# G32R501 register map
Vendor: Geehy Semiconductor Co., Ltd.; Series: G32R5; File version: 1.0
CPU: CM55 r0p1, little endian, MPU, FPU, double-precision FPU, DSP, VTOR, 4 interrupt priority bits
Registers are 32-bit, read-write, reset 0x0 unless marked. A register's access mark holds for its fields unless they carry their own. Offsets are from the block's base; [hi:lo] are bit positions; {n}, {i} and the like mark numbered series.

## DCS_COMMON — Dual Code Security for common
Base 0x500240E0
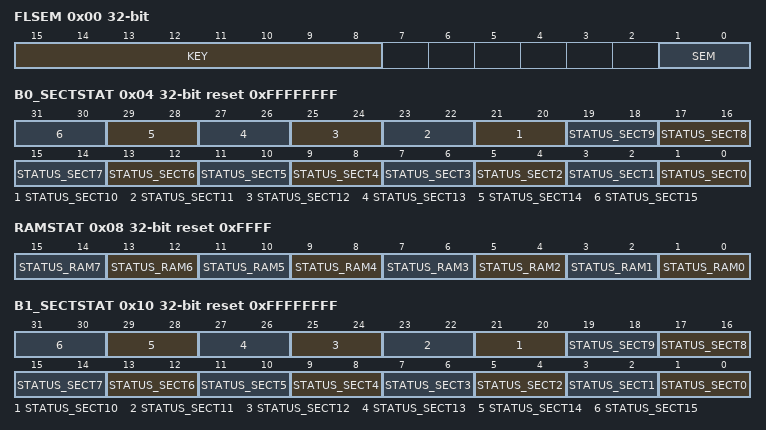
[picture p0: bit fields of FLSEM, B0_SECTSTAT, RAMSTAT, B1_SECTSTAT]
0x00 FLSEM
  [15:8] KEY
  [1:0] SEM — Flash Wrapper written mode configuration
0x04 B0_SECTSTAT ro reset 0xFFFFFFFF
  [2n+1:2n] STATUS_SECT{n} (n=0..15) — Flash BANK0 Sector x Flag
0x08 RAMSTAT ro reset 0xFFFF
  [2n+1:2n] STATUS_RAM{n} (n=0..7) — RAM Flag
0x10 B1_SECTSTAT ro reset 0xFFFFFFFF
  [2n+1:2n] STATUS_SECT{n} (n=0..15) — Flash BANK1 Sector x Flag
0x14 SECERRSTAT ro
  [0] ERR — Error loading security configuration from USER OTP Flag
0x18 SECERRCLR
  [0] ERR — Clear Security Configuration Load Error Status Bit
0x1C SECERRFRC
  [0] ERR — Set Security Configuration Load Error Status Bit

## DCS_B1Z1 — Dual Code Security for BANK1 Zone1
Base 0x50024200
0x00 B1Z1LP ro reset 0xFFFFFFFF
  [28:0] POINTER — Zone 1 Link Pointer for flash BANK1
0x0C B1Z1LPERR ro
  [28:0] POINTERERR — Link Pointer error for flash BANK1
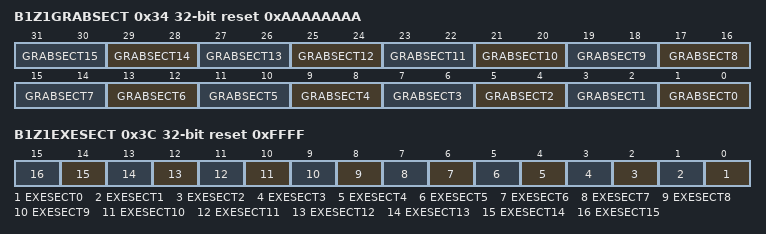
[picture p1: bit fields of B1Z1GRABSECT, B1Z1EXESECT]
0x34 B1Z1GRABSECT ro reset 0xAAAAAAAA
  [2n+1:2n] GRABSECT{n} (n=0..15) — Zone 1 Grab Flash BANK1 Sectors x configuration
0x3C B1Z1EXESECT ro reset 0xFFFF
  [n] EXESECT{n} (n=0..15) — Zone 1 Flash BANK1 Sector x Execute_Only disabled

## DCS_B1Z2 — Dual Code Security for BANK1 Zone2
Base 0x50024280
0x00 B1Z2LP ro reset 0xFFFFFFFF
  [28:0] POINTER — Zone 2 Link Pointer for flash BANK1
0x0C B1Z2LPERR ro
  [28:0] POINTERERR — Link Pointer error for flash BANK1
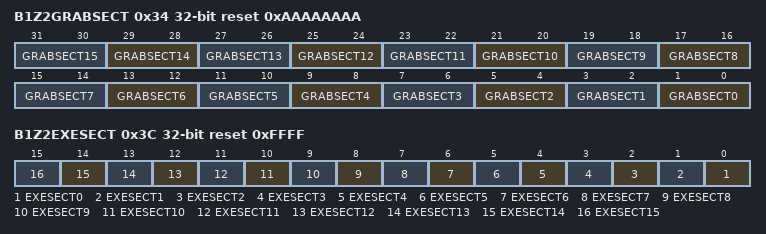
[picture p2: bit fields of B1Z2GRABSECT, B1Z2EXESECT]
0x34 B1Z2GRABSECT ro reset 0xAAAAAAAA
  [2n+1:2n] GRABSECT{n} (n=0..15) — Zone 2 Grab Flash BANK1 Sectors x configuration
0x3C B1Z2EXESECT ro reset 0xFFFF
  [n] EXESECT{n} (n=0..15) — Zone 2 Flash BANK1 Sector x Execute_Only disabled

## DMA — Direct Memory Access (DMA)
Base 0x50110C00
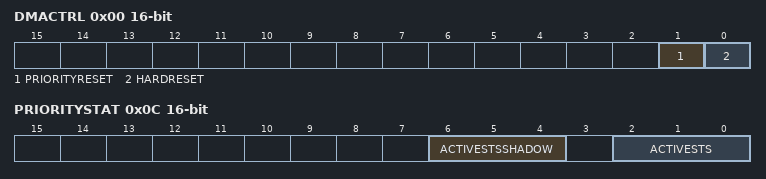
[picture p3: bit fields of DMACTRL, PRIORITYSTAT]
0x00 DMACTRL 16-bit — DMA Control Register
  [1] PRIORITYRESET — Priority Reset Bit
  [0] HARDRESET — Hard Reset Bit
0x02 DEBUGCTRL 16-bit — Debug Control Register
  [15] FREE — Debug Mode Bit
0x08 PRIORITYCTRL1 16-bit — Priority Control 1 Register
  [0] CH1PRIORITY — Ch1 Priority Bit
0x0C PRIORITYSTAT 16-bit — Priority Status Register
  [6:4] ACTIVESTSSHADOW — Active Channel Status Shadow Bits
  [2:0] ACTIVESTS — Active Channel Status Bits

## DMA_CH1 — DMA_CH_REGS
Base 0x50110C40
Same registers: DMA_CH2 0x50110C80, DMA_CH3 0x50110CC0, DMA_CH4 0x50110D00, DMA_CH5 0x50110D40, DMA_CH6 0x50110D80
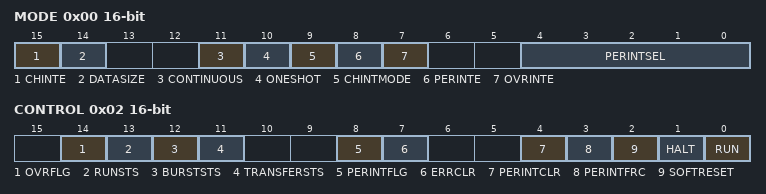
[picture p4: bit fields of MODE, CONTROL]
0x00 MODE 16-bit
  [15] CHINTE — Channel Interrupt Enable Bit
  [14] DATASIZE — Data Size Mode Bit
  [11] CONTINUOUS — Continuous Mode Bit
  [10] ONESHOT — One Shot Mode Bit
  [9] CHINTMODE — Channel Interrupt Mode
  [8] PERINTE — Peripheral Interrupt Enable
  [7] OVRINTE — Overflow Interrupt Enable
  [4:0] PERINTSEL — Peripheral Interrupt and Sync Select
0x02 CONTROL 16-bit
  [14] OVRFLG — Overflow Flag Bit
  [13] RUNSTS — Run Status Bit
  [12] BURSTSTS — Burst Status Bit
  [11] TRANSFERSTS — Transfer Status Bit
  [8] PERINTFLG — Interrupt Flag Bit
  [7] ERRCLR — Error Clear Bit
  [4] PERINTCLR — Interrupt Clear Bit
  [3] PERINTFRC — Interrupt Force Bit
  [2] SOFTRESET — Soft Reset Bit
  [1] HALT — Halt Bit
  [0] RUN — Run Bit
0x04 BURST_SIZE 16-bit
  [4:0] BURSTSIZE — Burst Transfer Size
0x06 BURST_COUNT 16-bit
  [4:0] BURSTCOUNT — Burst Transfer Size
0x08 SRC_BURST_STEP 16-bit — Source Burst Step Register
  [15:0] SRCBURSTSTEP — Source Burst Step
0x0A DST_BURST_STEP 16-bit — Destination Burst Step Register
  [15:0] DSTBURSTSTEP — Destination Burst Step
0x0C TRANSFER_SIZE 16-bit
  [15:0] TRANSFERSIZE
0x0E TRANSFER_COUNT 16-bit
  [15:0] TRANSFERCOUNT
0x10 SRC_TRANSFER_STEP 16-bit — Source Transfer Step Register
  [15:0] SRCTRANSFERSTEP — Source Transfer Step
0x12 DST_TRANSFER_STEP 16-bit — Destination Transfer Step Register
  [15:0] DSTTRANSFERSTEP — Destination Transfer Step
0x14 SRC_WRAP_SIZE 16-bit reset 0xFFFF — Source Wrap Size Register
  [15:0] WRAPSIZE — Source Wrap Size
0x16 SRC_WRAP_COUNT 16-bit — Source Wrap Count Register
  [15:0] WRAPSIZE — Source Wrap Count
0x18 SRC_WRAP_STEP 16-bit — Source Wrap Step Register
  [15:0] WRAPSTEP — Source Transfer Step
0x1A DST_WRAP_SIZE 16-bit reset 0xFFFF — Destination Wrap Size Register
  [15:0] WRAPSIZE — Destination Wrap Size
0x1C DST_WRAP_COUNT 16-bit — Destination Wrap Count Register
  [15:0] WRAPSIZE — Destination Wrap Count
0x1E DST_WRAP_STEP 16-bit — Destination Wrap Step Register
  [15:0] WRAPSTEP — Destination Transfer Step
0x20 SRC_BEG_ADDR_SHADOW — Source Begin Address Shadow Register
  [31:0] BEGADDR — Shadow Source Beginning Address
0x24 SRC_ADDR_SHADOW — Source Address Shadow Register
  [31:0] ADDR — Shadow Source Address
0x28 SRC_BEG_ADDR_ACTIVE — Source Begin Address Active Register
  [31:0] BEGADDR — Active Source Beginning Address
0x2C SRC_ADDR_ACTIVE — Source Address Active Register
  [31:0] ADDR — Active Source Address
0x30 DST_BEG_ADDR_SHADOW — Destination Begin Address Shadow Register
  [31:0] BEGADDR — Shadow Destination Beginning Address
0x34 DST_ADDR_SHADOW — Destination Address Shadow Register
  [31:0] ADDR — Shadow Destination Address
0x38 DST_BEG_ADDR_ACTIVE — Destination Begin Address Active Register
  [31:0] BEGADDR — Active Destination Beginning Address
0x3C DST_ADDR_ACTIVE — Destination Address Active Register
  [31:0] ADDR — Active Destination Address
